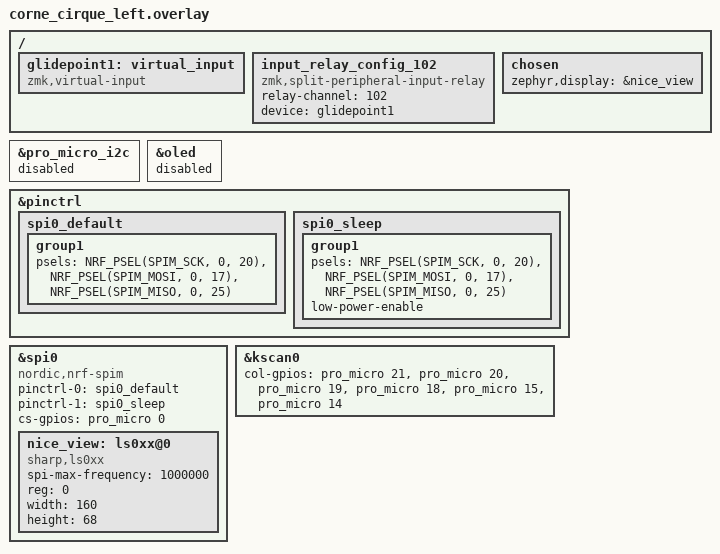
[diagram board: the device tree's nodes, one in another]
/*
 * Copyright (c) 2020 The ZMK Contributors
 *
 * SPDX-License-Identifier: MIT
 */

#include "corne_cirque.dtsi"

/* Disable default OLED */
&pro_micro_i2c {
    status = "disabled";
};

&oled {
    status = "disabled";
};

&pinctrl {
    spi0_default: spi0_default {
        group1 {
            psels = <NRF_PSEL(SPIM_SCK, 0, 20)>,
                    <NRF_PSEL(SPIM_MOSI, 0, 17)>,
                    <NRF_PSEL(SPIM_MISO, 0, 25)>; /* Unused */
        };
    };

    spi0_sleep: spi0_sleep {
        group1 {
            psels = <NRF_PSEL(SPIM_SCK, 0, 20)>,
                    <NRF_PSEL(SPIM_MOSI, 0, 17)>,
                    <NRF_PSEL(SPIM_MISO, 0, 25)>;
            low-power-enable;
        };
    };
};

&spi0 {
    compatible = "nordic,nrf-spim";
    status = "okay";
    pinctrl-0 = <&spi0_default>;
    pinctrl-1 = <&spi0_sleep>;
    pinctrl-names = "default", "sleep";
    cs-gpios = <&pro_micro 0 GPIO_ACTIVE_HIGH>;

    nice_view: ls0xx@0 {
        compatible = "sharp,ls0xx";
        spi-max-frequency = <1000000>;
        reg = <0>;
        width = <160>;
        height = <68>;
    };
};

&kscan0 {
    col-gpios
        = <&pro_micro 21 GPIO_ACTIVE_HIGH>
        , <&pro_micro 20 GPIO_ACTIVE_HIGH>
        , <&pro_micro 19 GPIO_ACTIVE_HIGH>
        , <&pro_micro 18 GPIO_ACTIVE_HIGH>
        , <&pro_micro 15 GPIO_ACTIVE_HIGH>
        , <&pro_micro 14 GPIO_ACTIVE_HIGH>
        ;
};

/ {
    /* define virtual input, will be resurrected for emitting input event */
    /* NOTE: set `device = <&glidepoint1>` in `zmk,input-listener` */
    glidepoint1: virtual_input {
        compatible = "zmk,virtual-input";
    };

    /* for central side, define (relay-channel)-to-(virtual-input) mapping */
    input_relay_config_102 {
        compatible = "zmk,split-peripheral-input-relay";
        
        /* channel id, used to filter incoming input event from split peripheral */
        /* NOTE: should matching relay-channel on peripheral overlay */
        relay-channel = <102>;

        /* virtual input device on central, which used to emit input event as an agent device */
        device = <&glidepoint1>;
    };

    chosen {
        zephyr,display = &nice_view;
    };
};
